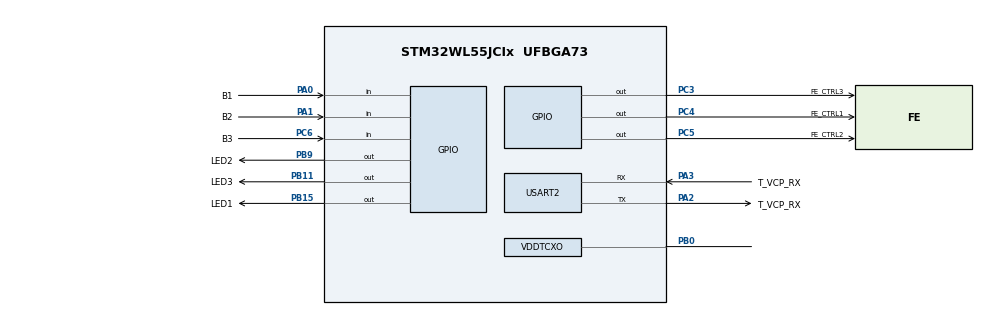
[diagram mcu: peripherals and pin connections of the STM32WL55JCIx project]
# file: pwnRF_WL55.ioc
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FREERTOS.Tasks01=initThread,24,512,initTask,Default,NULL,Dynamic,NULL,NULL
FREERTOS.configTIMER_TASK_PRIORITY=25
FREERTOS.configTOTAL_HEAP_SIZE=7000
FREERTOS.configUSE_NEWLIB_REENTRANT=1
Mcu.Family=STM32WL
Mcu.Name=STM32WL55JCIx
Mcu.Package=UFBGA73
NVIC.PriorityGroup=NVIC_PRIORITYGROUP_4
NVIC.TIM1_UP_IRQn=true\:0\:0\:false\:false\:true\:false\:false\:true
NVIC.TimeBase=TIM1_UP_IRQn
NVIC.TimeBaseIP=TIM1
NVIC.USART2_IRQn=true\:5\:0\:false\:false\:true\:true\:true\:true
OSC_IN.Mode=HSE-TCXO
OSC_IN.Signal=RCC_OSC_IN
PA0.GPIO_Label=B1
PA0.GPIO_PuPd=GPIO_PULLUP
PA0.Signal=GPIO_Input
PA1.GPIO_Label=B2
PA1.GPIO_PuPd=GPIO_PULLUP
PA1.Signal=GPIO_Input
PA13.Mode=Serial_Wire
PA13.Signal=DEBUG_JTMS-SWDIO
PA14.Mode=Serial_Wire
PA14.Signal=DEBUG_JTCK-SWCLK
PA2.GPIO_Label=T_VCP_RX
PA2.Mode=Asynchronous
PA2.Signal=USART2_TX
PA3.GPIO_Label=T_VCP_RX
PA3.Mode=Asynchronous
PA3.Signal=USART2_RX
PB0-VDD_TCXO.Mode=HSE-TCXO
PB0-VDD_TCXO.Signal=VDDTCXO
PB11.GPIO_Label=LED3
PB11.Signal=GPIO_Output
PB15.GPIO_Label=LED1
PB15.Signal=GPIO_Output
PB9.GPIO_FM9=__NULL
PB9.GPIO_Label=LED2
PB9.Signal=GPIO_Output
PC14-OSC32_IN.Mode=LSE-External-Oscillator
PC14-OSC32_IN.Signal=RCC_OSC32_IN
PC15-OSC32_OUT.Mode=LSE-External-Oscillator
PC15-OSC32_OUT.Signal=RCC_OSC32_OUT
PC3.GPIO_Label=FE_CTRL3
PC3.Signal=GPIO_Output
PC4.GPIO_Label=FE_CTRL1
PC4.Signal=GPIO_Output
PC5.GPIO_Label=FE_CTRL2
PC5.Signal=GPIO_Output
PC6.GPIO_Label=B3
PC6.GPIO_PuPd=GPIO_PULLUP
PC6.Signal=GPIO_Input
ProjectManager.HeapSize=0x200
ProjectManager.StackSize=0x400
ProjectManager.TargetToolchain=STM32CubeIDE
RCC.AHBFreq_Value=48000000
RCC.APB1Freq_Value=48000000
RCC.APB1TimFreq_Value=48000000
RCC.APB2Freq_Value=48000000
RCC.APB2TimFreq_Value=48000000
RCC.APB3Freq_Value=48000000
RCC.CortexFreq_Value=48000000
RCC.HCLKFreq_Value=48000000
RCC.HSE_VALUE=32000000
RCC.HSI_VALUE=16000000
RCC.LSE_VALUE=32768
RCC.MSIClockRange=RCC_MSIRANGE_11
RCC.SYSCLKFreq_VALUE=48000000
RCC.VCOOutputFreq_Value=384000000
SUBGHZ.BaudratePrescaler=SUBGHZSPI_BAUDRATEPRESCALER_4
SubGHz_Phy.BSP.number=3
SubGHz_Phy0.BSP.STBoard=false
SubGHz_Phy0.BSP.api=Unknown
SubGHz_Phy0.BSP.condition=SEM_RADIO_BOARD_INTERFACE_FOR_SUBGHZ_PHY
SubGHz_Phy0.BSP.i2caddr=0
SubGHz_Phy0.BSP.instance=PC3
SubGHz_Phy0.BSP.ip=GPIO
SubGHz_Phy0.BSP.mode=Output
SubGHz_Phy0.BSP.name=RF SW CTRL 3
SubGHz_Phy0.BSP.solution=PC3
SubGHz_Phy1.BSP.STBoard=false
SubGHz_Phy1.BSP.api=Unknown
SubGHz_Phy1.BSP.condition=SEM_RADIO_BOARD_INTERFACE_FOR_SUBGHZ_PHY
SubGHz_Phy1.BSP.i2caddr=0
SubGHz_Phy1.BSP.instance=PC4
SubGHz_Phy1.BSP.ip=GPIO
SubGHz_Phy1.BSP.mode=Output
SubGHz_Phy1.BSP.name=RF SW CTRL 1
SubGHz_Phy1.BSP.solution=PC4
SubGHz_Phy2.BSP.STBoard=false
SubGHz_Phy2.BSP.api=Unknown
SubGHz_Phy2.BSP.condition=SEM_RADIO_BOARD_INTERFACE_FOR_SUBGHZ_PHY
SubGHz_Phy2.BSP.i2caddr=0
SubGHz_Phy2.BSP.instance=PC5
SubGHz_Phy2.BSP.ip=GPIO
SubGHz_Phy2.BSP.mode=Output
SubGHz_Phy2.BSP.name=RF SW CTRL 2
SubGHz_Phy2.BSP.solution=PC5
USART2.FIFOMode=FIFOMODE_DISABLE
USART2.RXFIFOThreshold=RXFIFO_THRESHOLD_1EIGHTHFULL
USART2.TXFIFOThreshold=TXFIFO_THRESHOLD_1EIGHTHFULL
USART2.VirtualMode-Asynchronous=VM_ASYNC
VP_ADV_TRACE_VS_ADV_TRACE.Mode=ADV_TRACE_Enabled
VP_FREERTOS_VS_CMSIS_V2.Mode=CMSIS_V2
VP_MISC_VS_MISC.Mode=MISC_Enabled
VP_SUBGHZ_PHY_VS_SubGhzPhy.Mode=SubGhzPhy_Enabled
VP_SUBGHZ_VS_SUBGHZ.Mode=SUBGHZ_Activate
VP_SYS_VS_tim1.Mode=TIM1
VP_TIMER_VS_TIMER.Mode=TIMER_Enabled
VP_TINY_LPM_VS_TINY_LPM.Mode=TINY_LPM_Enabled
board=NUCLEO-WL55JC1

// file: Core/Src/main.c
/* USER CODE BEGIN Header */
/**
  ******************************************************************************
  * @file           : main.c
  * @brief          : Main program body
  ******************************************************************************
  * @attention
  *
  * <h2><center>&copy; Copyright (c) 2021 STMicroelectronics.
  * All rights reserved.</center></h2>
  *
  * This software component is licensed by ST under BSD 3-Clause license,
  * the "License"; You may not use this file except in compliance with the
  * License. You may obtain a copy of the License at:
  *                        opensource.org/licenses/BSD-3-Clause
  *
  ******************************************************************************
  */
/* USER CODE END Header */
#include "main.h"
#include "cmsis_os.h"
#include "subghz.h"
#include "app_subghz_phy.h"
#include "usart.h"
#include "gpio.h"

void SystemClock_Config(void);
void MX_FREERTOS_Init(void);

int main(void)
{

  /* MCU Configuration--------------------------------------------------------*/

  /* Reset of all peripherals, Initializes the Flash interface and the Systick. */
  HAL_Init();

  /* Configure the system clock */
  SystemClock_Config();

  /* Initialize all configured peripherals */
  MX_GPIO_Init();
  MX_USART2_UART_Init();
  MX_SUBGHZ_Init();

  /* Init scheduler */
  osKernelInitialize();  /* Call init function for freertos objects (in freertos.c) */
  MX_FREERTOS_Init();
  /* Start scheduler */
  osKernelStart();

  /* We should never get here as control is now taken by the scheduler */
  /* Infinite loop */
  while (1)
  {

  }
}

void SystemClock_Config(void)
{
  RCC_OscInitTypeDef RCC_OscInitStruct = {0};
  RCC_ClkInitTypeDef RCC_ClkInitStruct = {0};

  /** Configure LSE Drive Capability
  */
  HAL_PWR_EnableBkUpAccess();
  __HAL_RCC_LSEDRIVE_CONFIG(RCC_LSEDRIVE_LOW);
  /** Configure the main internal regulator output voltage
  */
  __HAL_PWR_VOLTAGESCALING_CONFIG(PWR_REGULATOR_VOLTAGE_SCALE1);
  /** Initializes the CPU, AHB and APB busses clocks
  */
  RCC_OscInitStruct.OscillatorType = RCC_OSCILLATORTYPE_LSE|RCC_OSCILLATORTYPE_MSI;
  RCC_OscInitStruct.LSEState = RCC_LSE_ON;
  RCC_OscInitStruct.MSIState = RCC_MSI_ON;
  RCC_OscInitStruct.MSICalibrationValue = RCC_MSICALIBRATION_DEFAULT;
  RCC_OscInitStruct.MSIClockRange = RCC_MSIRANGE_11;
  RCC_OscInitStruct.PLL.PLLState = RCC_PLL_NONE;
  if (HAL_RCC_OscConfig(&RCC_OscInitStruct) != HAL_OK)
  {
    Error_Handler();
  }
  /** Configure the SYSCLKSource, HCLK, PCLK1 and PCLK2 clocks dividers
  */
  RCC_ClkInitStruct.ClockType = RCC_CLOCKTYPE_HCLK3|RCC_CLOCKTYPE_HCLK
                              |RCC_CLOCKTYPE_SYSCLK|RCC_CLOCKTYPE_PCLK1
                              |RCC_CLOCKTYPE_PCLK2;
  RCC_ClkInitStruct.SYSCLKSource = RCC_SYSCLKSOURCE_MSI;
  RCC_ClkInitStruct.AHBCLKDivider = RCC_SYSCLK_DIV1;
  RCC_ClkInitStruct.APB1CLKDivider = RCC_HCLK_DIV1;
  RCC_ClkInitStruct.APB2CLKDivider = RCC_HCLK_DIV1;
  RCC_ClkInitStruct.AHBCLK3Divider = RCC_SYSCLK_DIV1;

  if (HAL_RCC_ClockConfig(&RCC_ClkInitStruct, FLASH_LATENCY_2) != HAL_OK)
  {
    Error_Handler();
  }
}

 /**
  * @brief  Period elapsed callback in non blocking mode
  * @note   This function is called  when TIM1 interrupt took place, inside
  * HAL_TIM_IRQHandler(). It makes a direct call to HAL_IncTick() to increment
  * a global variable "uwTick" used as application time base.
  * @param  htim : TIM handle
  * @retval None
  */
void HAL_TIM_PeriodElapsedCallback(TIM_HandleTypeDef *htim)
{
  if (htim->Instance == TIM1) {
    HAL_IncTick();
  }
}

void Error_Handler(void)
{
  __disable_irq();
  while (1)
  {
  }
}

/************************ (C) COPYRIGHT STMicroelectronics *****END OF FILE****/

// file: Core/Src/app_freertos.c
/* USER CODE BEGIN Header */
/**
  ******************************************************************************
  * File Name          : app_freertos.c
  * Description        : Code for freertos applications
  ******************************************************************************
  * @attention
  *
  * <h2><center>&copy; Copyright (c) 2021 STMicroelectronics.
  * All rights reserved.</center></h2>
  *
  * This software component is licensed by ST under Ultimate Liberty license
  * SLA0044, the "License"; You may not use this file except in compliance with
  * the License. You may obtain a copy of the License at:
  *                             www.st.com/SLA0044
  *
  ******************************************************************************
  */
/* USER CODE END Header */

#include "FreeRTOS.h"
#include "task.h"
#include "main.h"
#include "cmsis_os.h"

#include "app_subghz_phy.h"

/* USER CODE BEGIN Includes */
#include "subghz_phy_app.h"

#include "CLI/cli.h"
/* USER CODE END Includes */

/* Definitions for initThread */
osThreadId_t initThreadHandle;
const osThreadAttr_t initThread_attributes = {
  .name = "initThread",
  .priority = (osPriority_t) osPriorityNormal,
  .stack_size = 512 * 4
};

void initTask(void *argument);

void MX_FREERTOS_Init(void); /* (MISRA C 2004 rule 8.1) */

void MX_FREERTOS_Init(void) {

  /* Create the thread(s) */
  /* creation of initThread */
  initThreadHandle = osThreadNew(initTask, NULL, &initThread_attributes);

}

void initTask(void *argument)
{
  /* init code for SubGHz_Phy */
  MX_SubGHz_Phy_Init();
  /* USER CODE BEGIN initTask */

  /* Initialize Command Line */
  commandLineInit();

  /* Delete Init Task */
  osThreadTerminate(initThreadHandle);
  /* USER CODE END initTask */
}

/************************ (C) COPYRIGHT STMicroelectronics *****END OF FILE****/
